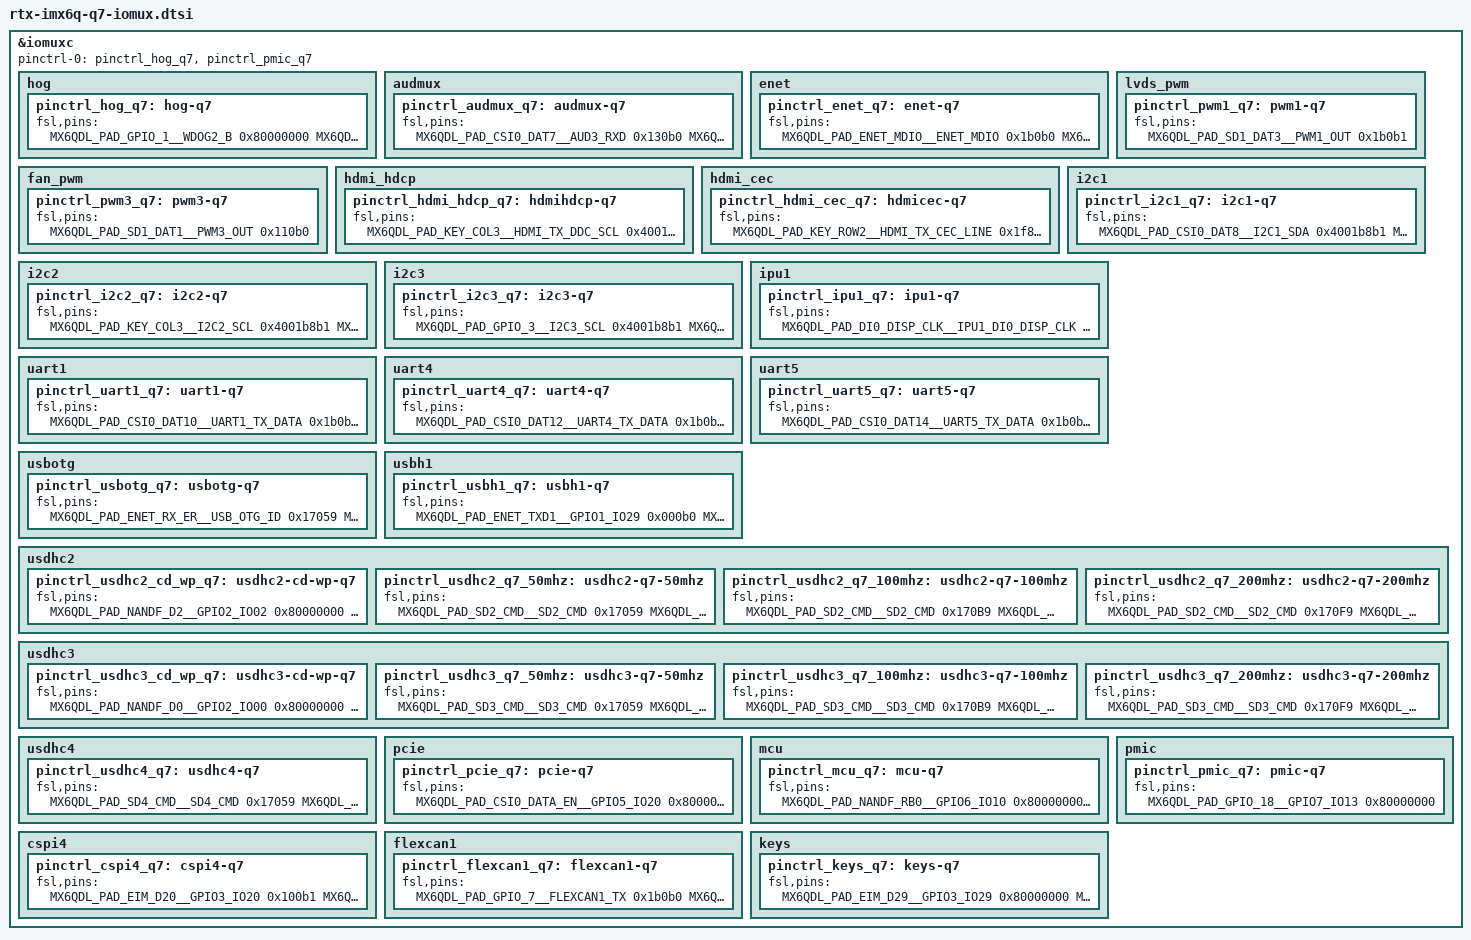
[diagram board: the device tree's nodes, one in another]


&iomuxc {
	pinctrl-names = "default";
	pinctrl-0 = <&pinctrl_hog_q7 &pinctrl_pmic_q7>;

	hog {
		pinctrl_hog_q7: hog-q7 {
			fsl,pins = <
				/* watchdog */
				MX6QDL_PAD_GPIO_1__WDOG2_B 					0x80000000	/* WDOG_B to reset pmic */
							
				/* Touch */
				MX6QDL_PAD_NANDF_CLE__GPIO6_IO07			0x80000000	/* Touch_INT */
				MX6QDL_PAD_NANDF_ALE__GPIO6_IO08			0x80000000	/* Touch_Reset */
				MX6QDL_PAD_EIM_D26__GPIO3_IO26				0x80000000	/* TS_INT */
				
				/* FAN GPIO */
				MX6QDL_PAD_EIM_D16__GPIO3_IO16				0x80000000	/* THRM */
				MX6QDL_PAD_EIM_D17__GPIO3_IO17				0x80000000	/* THRMTRIP */
				MX6QDL_PAD_SD1_DAT0__GPIO1_IO16				0x80000000	/* FAN_TACHOIN */
				
				/* LVDS */
				MX6QDL_PAD_NANDF_CS1__GPIO6_IO14			0x80000000	/* LVDS_BLEN */
				MX6QDL_PAD_NANDF_CS2__GPIO6_IO15			0x80000000	/* LVDS_PPEN */
				
				/* GPIO */
				MX6QDL_PAD_EIM_A25__GPIO5_IO02				0x80000000	/* GPIO1 */
				MX6QDL_PAD_EIM_D18__GPIO3_IO18				0x80000000	/* GPIO2 */
				MX6QDL_PAD_EIM_D19__GPIO3_IO19				0x80000000	/* GPIO3 */
				MX6QDL_PAD_KEY_COL1__GPIO4_IO08				0x80000000	/* GPIO4 */
				MX6QDL_PAD_EIM_D24__GPIO3_IO24				0x80000000	/* GPIO5 */
				MX6QDL_PAD_EIM_D25__GPIO3_IO25				0x80000000	/* GPIO6 */
				MX6QDL_PAD_EIM_D27__GPIO3_IO27				0x80000000	/* GPIO7 */
				MX6QDL_PAD_KEY_ROW1__GPIO4_IO09				0x80000000	/* GPIO8 */
				
				/* Audio Codec */
				MX6QDL_PAD_GPIO_0__CCM_CLKO1				0x000b0		/* SGTL5000 sys_mclk */
				MX6QDL_PAD_SD3_RST__GPIO7_IO08				0x80000000	/* HEADPHONE_DET */
				MX6QDL_PAD_GPIO_9__GPIO1_IO09				0x80000000	/* MICROPHONE_DET */
				MX6QDL_PAD_KEY_COL2__GPIO4_IO10				0x80000000	/* AUD_AMP_STBY_B */
				
				/* 3-AXIS */
				MX6QDL_PAD_SD1_CMD__GPIO1_IO18				0x80000000	/* ACCL_INT_IN */
			>;
		};
	};

	audmux {
		pinctrl_audmux_q7: audmux-q7 {
			fsl,pins = <
				MX6QDL_PAD_CSI0_DAT7__AUD3_RXD				0x130b0
				MX6QDL_PAD_CSI0_DAT4__AUD3_TXC				0x130b0
				MX6QDL_PAD_CSI0_DAT5__AUD3_TXD				0x110b0
				MX6QDL_PAD_CSI0_DAT6__AUD3_TXFS				0x130b0
			>;
		};
	};

	enet {
		pinctrl_enet_q7: enet-q7 {
			fsl,pins = <
				MX6QDL_PAD_ENET_MDIO__ENET_MDIO				0x1b0b0			/* RGMII_MDIO */
				MX6QDL_PAD_ENET_MDC__ENET_MDC				0x1b0b0			/* RGMII_MDC */
				MX6QDL_PAD_RGMII_TXC__RGMII_TXC				0x1b0b0
				MX6QDL_PAD_RGMII_TD0__RGMII_TD0				0x1b0b0
				MX6QDL_PAD_RGMII_TD1__RGMII_TD1				0x1b0b0
				MX6QDL_PAD_RGMII_TD2__RGMII_TD2				0x1b0b0
				MX6QDL_PAD_RGMII_TD3__RGMII_TD3				0x1b0b0
				MX6QDL_PAD_RGMII_TX_CTL__RGMII_TX_CTL			0x1b0b0
				MX6QDL_PAD_ENET_REF_CLK__ENET_TX_CLK			0x4001b0a8		/* ENET_REFCLK */
				MX6QDL_PAD_RGMII_RXC__RGMII_RXC				0x1b0b0
				MX6QDL_PAD_RGMII_RD0__RGMII_RD0				0x1b0b0
				MX6QDL_PAD_RGMII_RD1__RGMII_RD1				0x1b0b0
				MX6QDL_PAD_RGMII_RD2__RGMII_RD2				0x1b0b0
				MX6QDL_PAD_RGMII_RD3__RGMII_RD3				0x1b0b0
				MX6QDL_PAD_RGMII_RX_CTL__RGMII_RX_CTL			0x1b0b0
				MX6QDL_PAD_ENET_RXD1__GPIO1_IO26			0x000b1			/* RGMII_INT */
				MX6QDL_PAD_ENET_CRS_DV__GPIO1_IO25			0x1b0b0			/* RGMII_nRST */
			>;
		};
	};

	lvds_pwm {
		pinctrl_pwm1_q7: pwm1-q7 {
			fsl,pins = <
				MX6QDL_PAD_SD1_DAT3__PWM1_OUT				0x1b0b1		/* LVDS_BLT_CTRL PWM */
			>;
		};
	};

	fan_pwm {
		pinctrl_pwm3_q7: pwm3-q7 {
			fsl,pins = <
				MX6QDL_PAD_SD1_DAT1__PWM3_OUT				0x110b0		/* FAN_PWMOUT */
			>;
		};
	};
	
	hdmi_hdcp {
		pinctrl_hdmi_hdcp_q7: hdmihdcp-q7 {
			fsl,pins = <
				MX6QDL_PAD_KEY_COL3__HDMI_TX_DDC_SCL		0x4001b8b1
				MX6QDL_PAD_KEY_ROW3__HDMI_TX_DDC_SDA		0x4001b8b1
			>;
		};
	};

	hdmi_cec {
		pinctrl_hdmi_cec_q7: hdmicec-q7 {
			fsl,pins = <
				MX6QDL_PAD_KEY_ROW2__HDMI_TX_CEC_LINE		0x1f8b0
			>;
		};
	};

	i2c1 {
		pinctrl_i2c1_q7: i2c1-q7 {
			fsl,pins = <
				MX6QDL_PAD_CSI0_DAT8__I2C1_SDA			0x4001b8b1
				MX6QDL_PAD_CSI0_DAT9__I2C1_SCL			0x4001b8b1
			>;
		};
	};

	i2c2 {
		pinctrl_i2c2_q7: i2c2-q7 {
			fsl,pins = <
				MX6QDL_PAD_KEY_COL3__I2C2_SCL			0x4001b8b1
				MX6QDL_PAD_KEY_ROW3__I2C2_SDA			0x4001b8b1
			>;
		};
	};

	i2c3 {
		pinctrl_i2c3_q7: i2c3-q7 {
			fsl,pins = <
				MX6QDL_PAD_GPIO_3__I2C3_SCL			0x4001b8b1
				MX6QDL_PAD_GPIO_6__I2C3_SDA			0x4001b8b1
			>;
		};
	};

	ipu1 {
		pinctrl_ipu1_q7: ipu1-q7 {
			fsl,pins = <
				MX6QDL_PAD_DI0_DISP_CLK__IPU1_DI0_DISP_CLK	0x10					/* DISP0_CLK */
				MX6QDL_PAD_DI0_PIN15__IPU1_DI0_PIN15		0x10					/* DE */
				MX6QDL_PAD_DI0_PIN2__IPU1_DI0_PIN02			0x10					/* HSync */
				MX6QDL_PAD_DI0_PIN3__IPU1_DI0_PIN03			0x10					/* VSync */
				MX6QDL_PAD_DI0_PIN4__IPU1_DI0_PIN04			0x80000000				/* Contrast */
				MX6QDL_PAD_DISP0_DAT0__IPU1_DISP0_DATA00	0x10
				MX6QDL_PAD_DISP0_DAT1__IPU1_DISP0_DATA01	0x10
				MX6QDL_PAD_DISP0_DAT2__IPU1_DISP0_DATA02	0x10
				MX6QDL_PAD_DISP0_DAT3__IPU1_DISP0_DATA03	0x10
				MX6QDL_PAD_DISP0_DAT4__IPU1_DISP0_DATA04	0x10
				MX6QDL_PAD_DISP0_DAT5__IPU1_DISP0_DATA05	0x10
				MX6QDL_PAD_DISP0_DAT6__IPU1_DISP0_DATA06	0x10
				MX6QDL_PAD_DISP0_DAT7__IPU1_DISP0_DATA07	0x10
				MX6QDL_PAD_DISP0_DAT8__IPU1_DISP0_DATA08	0x10
				MX6QDL_PAD_DISP0_DAT9__IPU1_DISP0_DATA09	0x10
				MX6QDL_PAD_DISP0_DAT10__IPU1_DISP0_DATA10	0x10
				MX6QDL_PAD_DISP0_DAT11__IPU1_DISP0_DATA11	0x10
				MX6QDL_PAD_DISP0_DAT12__IPU1_DISP0_DATA12	0x10
				MX6QDL_PAD_DISP0_DAT13__IPU1_DISP0_DATA13	0x10
				MX6QDL_PAD_DISP0_DAT14__IPU1_DISP0_DATA14	0x10
				MX6QDL_PAD_DISP0_DAT15__IPU1_DISP0_DATA15	0x10
				MX6QDL_PAD_DISP0_DAT16__IPU1_DISP0_DATA16	0x10
				MX6QDL_PAD_DISP0_DAT17__IPU1_DISP0_DATA17	0x10
				MX6QDL_PAD_DISP0_DAT18__IPU1_DISP0_DATA18	0x10
				MX6QDL_PAD_DISP0_DAT19__IPU1_DISP0_DATA19	0x10
				MX6QDL_PAD_DISP0_DAT20__IPU1_DISP0_DATA20	0x10
				MX6QDL_PAD_DISP0_DAT21__IPU1_DISP0_DATA21	0x10
				MX6QDL_PAD_DISP0_DAT22__IPU1_DISP0_DATA22	0x10
				MX6QDL_PAD_DISP0_DAT23__IPU1_DISP0_DATA23	0x10
			>;
		};

	};

	uart1 {
		pinctrl_uart1_q7: uart1-q7 {
			fsl,pins = <
				MX6QDL_PAD_CSI0_DAT10__UART1_TX_DATA		0x1b0b1
				MX6QDL_PAD_CSI0_DAT11__UART1_RX_DATA		0x1b0b1
			>;
		};
	};

	uart4 {
		pinctrl_uart4_q7: uart4-q7 {
			fsl,pins = <
				MX6QDL_PAD_CSI0_DAT12__UART4_TX_DATA		0x1b0b1
				MX6QDL_PAD_CSI0_DAT13__UART4_RX_DATA		0x1b0b1
				MX6QDL_PAD_CSI0_DAT17__UART4_CTS_B		0x1b0b1
				MX6QDL_PAD_CSI0_DAT16__UART4_RTS_B		0x1b0b1
			>;
		};
	};

	uart5 {
		pinctrl_uart5_q7: uart5-q7 {
			fsl,pins = <
				MX6QDL_PAD_CSI0_DAT14__UART5_TX_DATA		0x1b0b1
				MX6QDL_PAD_CSI0_DAT15__UART5_RX_DATA		0x1b0b1
				MX6QDL_PAD_KEY_ROW4__UART5_CTS_B		0x1b0b1
				MX6QDL_PAD_KEY_COL4__UART5_RTS_B		0x1b0b1
			>;
		};
	};


	usbotg {
		pinctrl_usbotg_q7: usbotg-q7 {
			fsl,pins = <
				MX6QDL_PAD_ENET_RX_ER__USB_OTG_ID			0x17059
				MX6QDL_PAD_KEY_COL0__GPIO4_IO06				0x000b0				/* USB_OTG_PWR_EN */
				MX6QDL_PAD_KEY_ROW0__GPIO4_IO07				0x80000000			/* USB_OTG_OC */
			>;
		};
	};

	usbh1 {
		pinctrl_usbh1_q7: usbh1-q7 {
			fsl,pins = <
				MX6QDL_PAD_ENET_TXD1__GPIO1_IO29			0x000b0				/* USB_H1_PWR_EN */
				MX6QDL_PAD_EIM_D30__USB_H1_OC				0x1b0b0				/* USB_H1_OC */
				MX6QDL_PAD_EIM_D23__GPIO3_IO23				0x80000000			/* USB_HUB_RESET_B */
			>;
		};
	};

	usdhc2 {
		pinctrl_usdhc2_cd_wp_q7: usdhc2-cd-wp-q7 {
			fsl,pins = <
				MX6QDL_PAD_NANDF_D2__GPIO2_IO02				0x80000000	/* SD2_CD */
				MX6QDL_PAD_NANDF_D3__GPIO2_IO03				0x80000000	/* SD2_WP */
			>;
		};
		
		pinctrl_usdhc2_q7_50mhz: usdhc2-q7-50mhz {						/* 50Mhz */
			fsl,pins = <
				MX6QDL_PAD_SD2_CMD__SD2_CMD					0x17059
				MX6QDL_PAD_SD2_CLK__SD2_CLK					0x10059
				MX6QDL_PAD_SD2_DAT0__SD2_DATA0				0x17059
				MX6QDL_PAD_SD2_DAT1__SD2_DATA1				0x17059
				MX6QDL_PAD_SD2_DAT2__SD2_DATA2				0x17059
				MX6QDL_PAD_SD2_DAT3__SD2_DATA3				0x17059
			>;
		};

		pinctrl_usdhc2_q7_100mhz: usdhc2-q7-100mhz { 					/* 100Mhz */
			fsl,pins = <
				MX6QDL_PAD_SD2_CMD__SD2_CMD					0x170B9
				MX6QDL_PAD_SD2_CLK__SD2_CLK					0x100B9
				MX6QDL_PAD_SD2_DAT0__SD2_DATA0				0x170B9
				MX6QDL_PAD_SD2_DAT1__SD2_DATA1				0x170B9
				MX6QDL_PAD_SD2_DAT2__SD2_DATA2				0x170B9
				MX6QDL_PAD_SD2_DAT3__SD2_DATA3				0x170B9
			>;
		};

		pinctrl_usdhc2_q7_200mhz: usdhc2-q7-200mhz { 					/* 200Mhz */
			fsl,pins = <
				MX6QDL_PAD_SD2_CMD__SD2_CMD					0x170F9
				MX6QDL_PAD_SD2_CLK__SD2_CLK					0x100F9
				MX6QDL_PAD_SD2_DAT0__SD2_DATA0				0x170F9
				MX6QDL_PAD_SD2_DAT1__SD2_DATA1				0x170F9
				MX6QDL_PAD_SD2_DAT2__SD2_DATA2				0x170F9
				MX6QDL_PAD_SD2_DAT3__SD2_DATA3				0x170F9
			>;
		};
	};

	usdhc3 {
		pinctrl_usdhc3_cd_wp_q7: usdhc3-cd-wp-q7 {
			fsl,pins = <
				MX6QDL_PAD_NANDF_D0__GPIO2_IO00				0x80000000	/* SD3_CD */
				MX6QDL_PAD_NANDF_D1__GPIO2_IO01				0x80000000	/* SD3_WP */
			>;
		};

		pinctrl_usdhc3_q7_50mhz: usdhc3-q7-50mhz {						/* 50Mhz */
			fsl,pins = <
				MX6QDL_PAD_SD3_CMD__SD3_CMD				0x17059
				MX6QDL_PAD_SD3_CLK__SD3_CLK				0x10059
				MX6QDL_PAD_SD3_DAT0__SD3_DATA0				0x17059
				MX6QDL_PAD_SD3_DAT1__SD3_DATA1				0x17059
				MX6QDL_PAD_SD3_DAT2__SD3_DATA2				0x17059
				MX6QDL_PAD_SD3_DAT3__SD3_DATA3				0x17059
				MX6QDL_PAD_SD3_DAT4__SD3_DATA4				0x17059
				MX6QDL_PAD_SD3_DAT5__SD3_DATA5				0x17059
				MX6QDL_PAD_SD3_DAT6__SD3_DATA6				0x17059
				MX6QDL_PAD_SD3_DAT7__SD3_DATA7				0x17059
			>;
		};

		pinctrl_usdhc3_q7_100mhz: usdhc3-q7-100mhz { 				/* 100Mhz */
			fsl,pins = <
				MX6QDL_PAD_SD3_CMD__SD3_CMD				0x170B9
				MX6QDL_PAD_SD3_CLK__SD3_CLK				0x100B9
				MX6QDL_PAD_SD3_DAT0__SD3_DATA0				0x170B9
				MX6QDL_PAD_SD3_DAT1__SD3_DATA1				0x170B9
				MX6QDL_PAD_SD3_DAT2__SD3_DATA2				0x170B9
				MX6QDL_PAD_SD3_DAT3__SD3_DATA3				0x170B9
				MX6QDL_PAD_SD3_DAT4__SD3_DATA4				0x170B9
				MX6QDL_PAD_SD3_DAT5__SD3_DATA5				0x170B9
				MX6QDL_PAD_SD3_DAT6__SD3_DATA6				0x170B9
				MX6QDL_PAD_SD3_DAT7__SD3_DATA7				0x170B9
			>;
		};

		pinctrl_usdhc3_q7_200mhz: usdhc3-q7-200mhz { 				/* 200Mhz */
			fsl,pins = <
				MX6QDL_PAD_SD3_CMD__SD3_CMD				0x170F9
				MX6QDL_PAD_SD3_CLK__SD3_CLK				0x100F9
				MX6QDL_PAD_SD3_DAT0__SD3_DATA0				0x170F9
				MX6QDL_PAD_SD3_DAT1__SD3_DATA1				0x170F9
				MX6QDL_PAD_SD3_DAT2__SD3_DATA2				0x170F9
				MX6QDL_PAD_SD3_DAT3__SD3_DATA3				0x170F9
				MX6QDL_PAD_SD3_DAT4__SD3_DATA4				0x170F9
				MX6QDL_PAD_SD3_DAT5__SD3_DATA5				0x170F9
				MX6QDL_PAD_SD3_DAT6__SD3_DATA6				0x170F9
				MX6QDL_PAD_SD3_DAT7__SD3_DATA7				0x170F9
			>;
		};
	};

	usdhc4 {
		pinctrl_usdhc4_q7: usdhc4-q7 {
			fsl,pins = <
				MX6QDL_PAD_SD4_CMD__SD4_CMD				0x17059
				MX6QDL_PAD_SD4_CLK__SD4_CLK				0x10059
				MX6QDL_PAD_SD4_DAT0__SD4_DATA0				0x17059
				MX6QDL_PAD_SD4_DAT1__SD4_DATA1				0x17059
				MX6QDL_PAD_SD4_DAT2__SD4_DATA2				0x17059
				MX6QDL_PAD_SD4_DAT3__SD4_DATA3				0x17059
				MX6QDL_PAD_SD4_DAT4__SD4_DATA4				0x17059
				MX6QDL_PAD_SD4_DAT5__SD4_DATA5				0x17059
				MX6QDL_PAD_SD4_DAT6__SD4_DATA6				0x17059
				MX6QDL_PAD_SD4_DAT7__SD4_DATA7				0x17059
			>;
		};
	};

	pcie {
		pinctrl_pcie_q7: pcie-q7 {
			fsl,pins = <
				MX6QDL_PAD_CSI0_DATA_EN__GPIO5_IO20			0x80000000	/* PCIE_WAKE_B */
				MX6QDL_PAD_GPIO_16__GPIO7_IO11				0x80000000	/* PCIE_DIS_B */
				MX6QDL_PAD_GPIO_17__GPIO7_IO12				0x80000000	/* PCIE_RST */
			>;
		};
	};

	mcu {
		pinctrl_mcu_q7: mcu-q7 {
			fsl,pins = <
				MX6QDL_PAD_NANDF_RB0__GPIO6_IO10			0x80000000	/* MCU Reset */
				MX6QDL_PAD_NANDF_WP_B__GPIO6_IO09			0x80000000	/* MCU_UPDATE_PWR_ON */
				MX6QDL_PAD_NANDF_CS0__GPIO6_IO11			0x80000000	/* MCU_BOOT_EN */
				MX6QDL_PAD_EIM_D31__GPIO3_IO31				0x80000000	/* MCU_INT */
			>;
		};
	};

	pmic {
		pinctrl_pmic_q7: pmic-q7 {
			fsl,pins = <
				MX6QDL_PAD_GPIO_18__GPIO7_IO13				0x80000000	/* PMIC INT */
			>;
		};
	};

	cspi4 {
		pinctrl_cspi4_q7: cspi4-q7 {
			fsl,pins = <
				MX6QDL_PAD_EIM_D20__GPIO3_IO20				0x100b1		/* CSPI4_CS0 */
				MX6QDL_PAD_EIM_D21__ECSPI4_SCLK				0x100b1		/* CSPI4_CLK */
				MX6QDL_PAD_EIM_D22__ECSPI4_MISO				0x100b1		/* CSPI4_MISO */
				MX6QDL_PAD_EIM_D28__ECSPI4_MOSI				0x100b1		/* CSPI4_MOSI */
			>;
		};
	};

	flexcan1 {
		pinctrl_flexcan1_q7: flexcan1-q7 {
			fsl,pins = <
				MX6QDL_PAD_GPIO_7__FLEXCAN1_TX				0x1b0b0		/* CAN1_TX */
				MX6QDL_PAD_GPIO_8__FLEXCAN1_RX				0x1b0b0		/* CAN1_RX */
				MX6QDL_PAD_GPIO_19__GPIO4_IO05				0x1b0b0		/* CAN1_STBY */
			>;
		};
	};

	keys {
		pinctrl_keys_q7: keys-q7 {
			fsl,pins = <	
					/* special key */
				MX6QDL_PAD_EIM_D29__GPIO3_IO29				0x80000000	/* PWR_RTN_SNS */
				MX6QDL_PAD_GPIO_4__GPIO1_IO04				0x80000000	/* Volume Up */
				MX6QDL_PAD_GPIO_5__GPIO1_IO05				0x80000000	/* Volume Down */
				MX6QDL_PAD_GPIO_2__GPIO1_IO02				0x80000000	/* BACK */
				MX6QDL_PAD_NANDF_CS3__GPIO6_IO16			0x80000000	/* HOME */
			>;
		};
	};
};
